VERSION "ZephyrECU CI fixtures"
NS_ :

BS_:
BU_: ECU Tester

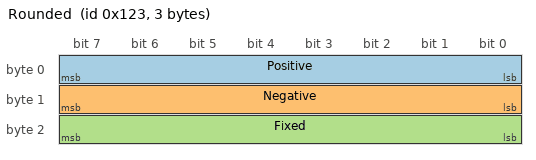
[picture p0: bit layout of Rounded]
BO_ 291 Rounded: 3 Tester
 SG_ Positive : 0|8@1+ (0.5,10) [10.1|20.9] "" ECU
 SG_ Negative : 15|8@0- (0.25,-10) [-12.9|-8.1] "" ECU
 SG_ Fixed : 16|8@1+ (1,0) [7|7] "" ECU
